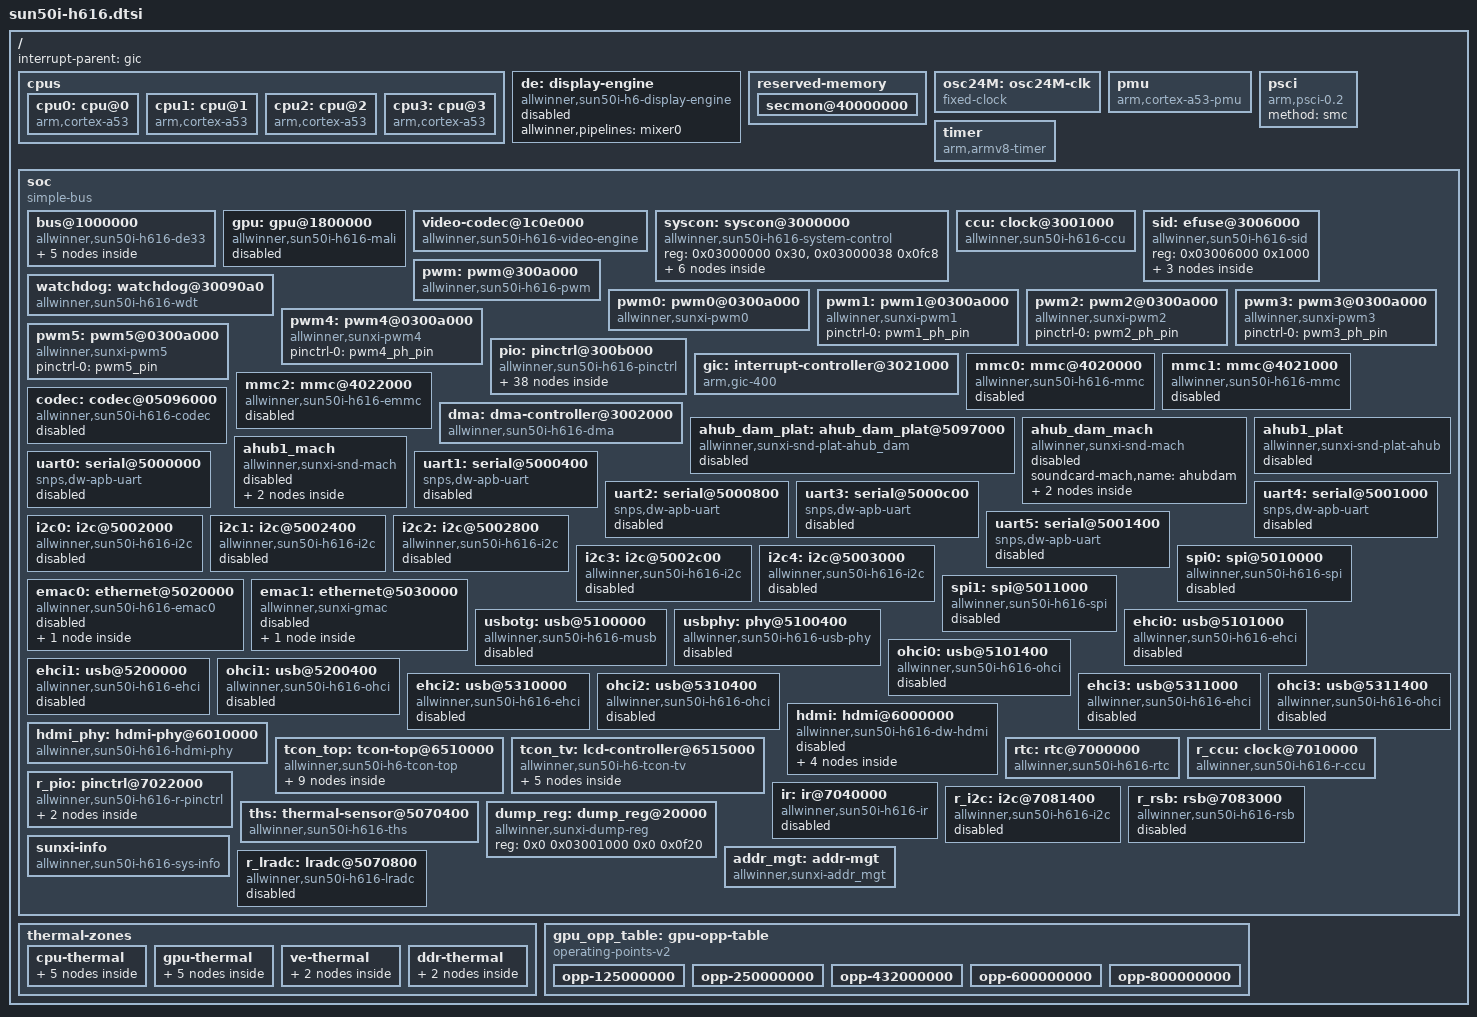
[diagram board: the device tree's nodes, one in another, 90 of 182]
// SPDX-License-Identifier: (GPL-2.0+ OR MIT)
// Copyright (C) 2020 Arm Ltd.
// based on the H6 dtsi, which is:
//   Copyright (C) 2017 Icenowy Zheng <icenowy@aosc.io>

#include <dt-bindings/interrupt-controller/arm-gic.h>
#include <dt-bindings/clock/sun50i-h616-ccu.h>
#include <dt-bindings/clock/sun50i-h6-r-ccu.h>
#include <dt-bindings/clock/sun6i-rtc.h>
#include <dt-bindings/clock/sun8i-de2.h>
#include <dt-bindings/clock/sun8i-tcon-top.h>
#include <dt-bindings/reset/sun50i-h616-ccu.h>
#include <dt-bindings/reset/sun50i-h6-r-ccu.h>
#include <dt-bindings/reset/sun8i-de2.h>
#include <dt-bindings/thermal/thermal.h>

/ {
	interrupt-parent = <&gic>;
	#address-cells = <2>;
	#size-cells = <2>;

	cpus {
		#address-cells = <1>;
		#size-cells = <0>;

		cpu0: cpu@0 {
			compatible = "arm,cortex-a53";
			device_type = "cpu";
			reg = <0>;
			enable-method = "psci";
			clocks = <&ccu CLK_CPUX>;
			clock-latency-ns = <244144>; /* 8 32k periods */
			#cooling-cells = <2>;
			operating-points-v2 = <&cpu_opp_table>;
		};

		cpu1: cpu@1 {
			compatible = "arm,cortex-a53";
			device_type = "cpu";
			reg = <1>;
			enable-method = "psci";
			clocks = <&ccu CLK_CPUX>;
			clock-latency-ns = <244144>; /* 8 32k periods */
			#cooling-cells = <2>;
			operating-points-v2 = <&cpu_opp_table>;
		};

		cpu2: cpu@2 {
			compatible = "arm,cortex-a53";
			device_type = "cpu";
			reg = <2>;
			enable-method = "psci";
			clocks = <&ccu CLK_CPUX>;
			clock-latency-ns = <244144>; /* 8 32k periods */
			#cooling-cells = <2>;
			operating-points-v2 = <&cpu_opp_table>;
		};

		cpu3: cpu@3 {
			compatible = "arm,cortex-a53";
			device_type = "cpu";
			reg = <3>;
			enable-method = "psci";
			clocks = <&ccu CLK_CPUX>;
			clock-latency-ns = <244144>; /* 8 32k periods */
			#cooling-cells = <2>;
			operating-points-v2 = <&cpu_opp_table>;
		};
	};

	de: display-engine {
		compatible = "allwinner,sun50i-h6-display-engine";
		allwinner,pipelines = <&mixer0>;
		status = "disabled";
	};

	reserved-memory {
		#address-cells = <2>;
		#size-cells = <2>;
		ranges;

		/*
		 * 512 KiB reserved for Trusted Firmware-A (BL31).
		 * This is added by BL31 itself, but some bootloaders fail
		 * to propagate this into the DTB handed to kernels.
		 */
		secmon@40000000 {
			reg = <0x0 0x40000000 0x0 0x80000>;
			no-map;
		};
	};

	osc24M: osc24M-clk {
		#clock-cells = <0>;
		compatible = "fixed-clock";
		clock-frequency = <24000000>;
		clock-output-names = "osc24M";
	};

	pmu {
		compatible = "arm,cortex-a53-pmu";
		interrupts = <GIC_SPI 140 IRQ_TYPE_LEVEL_HIGH>,
			     <GIC_SPI 141 IRQ_TYPE_LEVEL_HIGH>,
			     <GIC_SPI 142 IRQ_TYPE_LEVEL_HIGH>,
			     <GIC_SPI 143 IRQ_TYPE_LEVEL_HIGH>;
		interrupt-affinity = <&cpu0>, <&cpu1>, <&cpu2>, <&cpu3>;
	};

	psci {
		compatible = "arm,psci-0.2";
		method = "smc";
	};

	timer {
		compatible = "arm,armv8-timer";
		arm,no-tick-in-suspend;
		interrupts = <GIC_PPI 13
			(GIC_CPU_MASK_SIMPLE(4) | IRQ_TYPE_LEVEL_HIGH)>,
			     <GIC_PPI 14
			(GIC_CPU_MASK_SIMPLE(4) | IRQ_TYPE_LEVEL_HIGH)>,
			     <GIC_PPI 11
			(GIC_CPU_MASK_SIMPLE(4) | IRQ_TYPE_LEVEL_HIGH)>,
			     <GIC_PPI 10
			(GIC_CPU_MASK_SIMPLE(4) | IRQ_TYPE_LEVEL_HIGH)>;
	};

	soc {
		compatible = "simple-bus";
		#address-cells = <1>;
		#size-cells = <1>;
		ranges = <0x0 0x0 0x0 0x40000000>;

		bus@1000000 {
			compatible = "allwinner,sun50i-h616-de33",
				     "allwinner,sun50i-a64-de2";
			reg = <0x1000000 0x400000>;
			allwinner,sram = <&de3_sram 1>;
			#address-cells = <1>;
			#size-cells = <1>;
			ranges = <0 0x1000000 0x400000>;

			display_clocks: clock@8000 {
				compatible = "allwinner,sun50i-h616-de33-clk";
				reg = <0x8000 0x100>;
				clocks = <&ccu CLK_DE>, <&ccu CLK_BUS_DE>;
				clock-names = "mod", "bus";
				resets = <&ccu RST_BUS_DE>;
				#clock-cells = <1>;
				#reset-cells = <1>;
			};

			mixer0: mixer@100000 {
				compatible = "allwinner,sun50i-h616-de33-mixer-0";
				reg = <0x100000 0x100000>,
				      <0x8100 0x40>,
				      <0x280000 0x20000>;
				clocks = <&display_clocks CLK_BUS_MIXER0>,
					 <&display_clocks CLK_MIXER0>;
				clock-names = "bus", "mod";
				resets = <&display_clocks RST_MIXER0>;

				ports {
					#address-cells = <1>;
					#size-cells = <0>;

					mixer0_out: port@1 {
						reg = <1>;

						mixer0_out_tcon_top_mixer0: endpoint {
							remote-endpoint = <&tcon_top_mixer0_in_mixer0>;
						};
					};
				};
			};
		};

		gpu: gpu@1800000 {
			compatible = "allwinner,sun50i-h616-mali",
			             "arm,mali-bifrost";
			reg = <0x1800000 0x40000>;
			interrupts = <GIC_SPI 95 IRQ_TYPE_LEVEL_HIGH>,
			             <GIC_SPI 96 IRQ_TYPE_LEVEL_HIGH>,
			             <GIC_SPI 97 IRQ_TYPE_LEVEL_HIGH>;
			interrupt-names = "job", "mmu", "gpu";
			clocks = <&ccu CLK_GPU0>, <&ccu CLK_BUS_GPU>;
			clock-names = "core", "bus";
			resets = <&ccu RST_BUS_GPU>;
			//operating-points-v2 = <&gpu_opp_table>;
			//#cooling-cells = <2>;
			status = "disabled";
		};

		video-codec@1c0e000 {
			compatible = "allwinner,sun50i-h616-video-engine";
			reg = <0x01c0e000 0x2000>;
			clocks = <&ccu CLK_BUS_VE>, <&ccu CLK_VE>,
				 <&ccu CLK_MBUS_VE>;
			clock-names = "ahb", "mod", "ram";
			resets = <&ccu RST_BUS_VE>;
			interrupts = <GIC_SPI 93 IRQ_TYPE_LEVEL_HIGH>;
			allwinner,sram = <&ve_sram 1>;
		};

		syscon: syscon@3000000 {
			compatible = "allwinner,sun50i-h616-system-control";
			reg = <0x03000000 0x30>,<0x03000038 0x0fc8>;
			#address-cells = <1>;
			#size-cells = <1>;
			ranges;

			sram_a2: sram@100000 {
				compatible = "mmio-sram";
				reg = <0x00100000 0x18000>;
				#address-cells = <1>;
				#size-cells = <1>;
				ranges = <0 0x00100000 0x18000>;

				scpi_sram: scpi-sram@17c00 {
					compatible = "arm,scp-shmem";
					reg = <0x17c00 0x200>;
				};
			};

			sram_c: sram@28000 {
				compatible = "mmio-sram";
				reg = <0x00028000 0x30000>;
				#address-cells = <1>;
				#size-cells = <1>;
				ranges = <0 0x00028000 0x30000>;

				de3_sram: sram-section@0 {
					compatible = "allwinner,sun50i-h616-sram-c",
						     "allwinner,sun50i-a64-sram-c";
					reg = <0x0000 0x1e000>;
				};
			};

			sram_c1: sram@1a00000 {
				compatible = "mmio-sram";
				reg = <0x01a00000 0x200000>;
				#address-cells = <1>;
				#size-cells = <1>;
				ranges = <0 0x01a00000 0x200000>;

				ve_sram: sram-section@0 {
					compatible = "allwinner,sun50i-h616-sram-c1";
					reg = <0x000000 0x200000>;
				};
			};
		};

		ccu: clock@3001000 {
			compatible = "allwinner,sun50i-h616-ccu";
			reg = <0x03001000 0x1000>;
			clocks = <&osc24M>, <&rtc CLK_OSC32K>, <&rtc CLK_IOSC>;
			clock-names = "hosc", "losc", "iosc";
			#clock-cells = <1>;
			#reset-cells = <1>;
		};

		sid: efuse@3006000 {
			compatible = "allwinner,sun50i-h616-sid";
			reg = <0x03006000 0x1000>;
			#address-cells = <1>;
			#size-cells = <1>;

			cpu_speed_grade: cpu-speed-grade@00 {
				reg = <0x00 0x02>;
			};

			ths_calibration: thermal-sensor-calibration@14 {
				reg = <0x14 0x8>;
			};

			ephy_calibration: ephy-calibration@2c {
				reg = <0x2c 0x2>;
			};
		};

		watchdog: watchdog@30090a0 {
			compatible = "allwinner,sun50i-h616-wdt",
				     "allwinner,sun6i-a31-wdt";
			reg = <0x030090a0 0x20>;
			interrupts = <GIC_SPI 50 IRQ_TYPE_LEVEL_HIGH>;
			clocks = <&osc24M>;
			status = "okay";
		};

		pwm: pwm@300a000 {
			compatible = "allwinner,sun50i-h616-pwm";
			reg = <0x0300a000 0x400>;
			clocks = <&osc24M>, <&ccu CLK_BUS_PWM>;
			clock-names = "mod", "bus";
			resets = <&ccu RST_BUS_PWM>;
			pwm-number = <6>;
			pwm-base = <0x0>;
			sunxi-pwms = <&pwm0>, <&pwm1>, <&pwm2>, <&pwm3>, <&pwm4>, <&pwm5>;
			#pwm-cells = <3>;
			status = "okay";
		};

		pwm0: pwm0@0300a000 {
			compatible = "allwinner,sunxi-pwm0";
		};

		pwm1: pwm1@0300a000 {
			compatible = "allwinner,sunxi-pwm1";
			pinctrl-names = "default";
			pinctrl-0 = <&pwm1_ph_pin>;
		};

		pwm2: pwm2@0300a000 {
			compatible = "allwinner,sunxi-pwm2";
			pinctrl-names = "default";
			pinctrl-0 = <&pwm2_ph_pin>;
		};

		pwm3: pwm3@0300a000 {
			compatible = "allwinner,sunxi-pwm3";
			pinctrl-names = "default";
			pinctrl-0 = <&pwm3_ph_pin>;
		};

		pwm4: pwm4@0300a000 {
			compatible = "allwinner,sunxi-pwm4";
			pinctrl-names = "default";
			pinctrl-0 = <&pwm4_ph_pin>;
		};

		pwm5: pwm5@0300a000 {
			compatible = "allwinner,sunxi-pwm5";
			pinctrl-names = "default";
			pinctrl-0 = <&pwm5_pin>;
		};

		pio: pinctrl@300b000 {
			compatible = "allwinner,sun50i-h616-pinctrl";
			reg = <0x0300b000 0x400>;
			interrupts = <GIC_SPI 51 IRQ_TYPE_LEVEL_HIGH>,
				     <GIC_SPI 52 IRQ_TYPE_LEVEL_HIGH>,
				     <GIC_SPI 53 IRQ_TYPE_LEVEL_HIGH>,
				     <GIC_SPI 43 IRQ_TYPE_LEVEL_HIGH>,
				     <GIC_SPI 54 IRQ_TYPE_LEVEL_HIGH>,
				     <GIC_SPI 55 IRQ_TYPE_LEVEL_HIGH>,
				     <GIC_SPI 56 IRQ_TYPE_LEVEL_HIGH>,
				     <GIC_SPI 57 IRQ_TYPE_LEVEL_HIGH>;
			clocks = <&ccu CLK_APB1>, <&osc24M>, <&rtc CLK_OSC32K>;
			clock-names = "apb", "hosc", "losc";
			gpio-controller;
			#gpio-cells = <3>;
			interrupt-controller;
			#interrupt-cells = <3>;

			ext_rgmii_pins: rgmii-pins {
				pins = "PI0", "PI1", "PI2", "PI3", "PI4",
				       "PI5", "PI7", "PI8", "PI9", "PI10",
				       "PI11", "PI12", "PI13", "PI14", "PI15",
				       "PI16";
				function = "emac0";
				drive-strength = <40>;
			};

			/omit-if-no-ref/
			i2c0_pi_pins: i2c0-pi-pins {
				pins = "PI5", "PI6";
				function = "i2c0";
			};

			/omit-if-no-ref/
			i2c1_ph_pins: i2c1-ph-pins {
				pins = "PH0", "PH1";
				function = "i2c1";
			};

			/omit-if-no-ref/
			i2c1_pi_pins: i2c1-pi-pins {
				pins = "PI7", "PI8";
				function = "i2c1";
			};

			/omit-if-no-ref/
			i2c2_ph_pins: i2c2-ph-pins {
				pins = "PH2", "PH3";
				function = "i2c2";
			};

			/omit-if-no-ref/
			i2c2_pi_pins: i2c2-pi-pins {
				pins = "PI9", "PI10";
				function = "i2c2";
			};

			/omit-if-no-ref/
			i2c3_ph_pins: i2c3-ph-pins {
				pins = "PH4", "PH5";
				function = "i2c3";
			};

			i2c3_pa_pins: i2c3-pa-pins {
				pins = "PA10", "PA11";
				function = "i2c3";
				bias-pull-up;
			};

			/omit-if-no-ref/
			i2c4_ph_pins: i2c4-ph-pins {
				pins = "PH6", "PH7";
				function = "i2c4";
			};

			/omit-if-no-ref/
			i2s3_pins: i2s3-pins {
				pins = "PH5", "PH6", "PH7", "PH8", "PH9";
				function = "i2s3";
			};

			ir_rx_pin: ir-rx-pin {
				pins = "PH10";
				function = "ir_rx";
			};

			/omit-if-no-ref/
			pwm1_ph_pin: pwm1-ph-pin {
				pins = "PH3";
				function = "pwm1";
			};

			/omit-if-no-ref/
			pwm2_ph_pin: pwm2-ph-pin {
				pins = "PH2";
				function = "pwm2";
			};

			/omit-if-no-ref/
			pwm3_ph_pin: pwm3-ph-pin {
				pins = "PH0";
				function = "pwm3";
			};

			/omit-if-no-ref/
			pwm4_ph_pin: pwm4-ph-pin {
				pins = "PH1";
				function = "pwm4";
			};

			/omit-if-no-ref/
			pwm5_pin: pwm5-pin {
				pins = "PA12";
				function = "pwm5";
			};

			/omit-if-no-ref/
			pwm1_pi_pin: pwm1-pi-pin {
				pins = "PI11";
				function = "pwm1";
			};

			/omit-if-no-ref/
			pwm2_pi_pin: pwm2-pi-pin {
				pins = "PI12";
				function = "pwm2";
			};

			/omit-if-no-ref/
			pwm3_pi_pin: pwm3-pi-pin {
				pins = "PI13";
				function = "pwm3";
			};

			/omit-if-no-ref/
			pwm4_pi_pin: pwm4-pi-pin {
				pins = "PI14";
				function = "pwm4";
			};

			mmc0_pins: mmc0-pins {
				pins = "PF0", "PF1", "PF2", "PF3",
				       "PF4", "PF5";
				function = "mmc0";
				drive-strength = <30>;
				bias-pull-up;
			};

			/omit-if-no-ref/
			mmc1_pins: mmc1-pins {
				pins = "PG0", "PG1", "PG2", "PG3",
				       "PG4", "PG5";
				function = "mmc1";
				drive-strength = <30>;
				bias-pull-up;
			};

			mmc2_pins: mmc2-pins {
				pins = "PC0", "PC1", "PC5", "PC6",
				       "PC8", "PC9", "PC10", "PC11",
				       "PC13", "PC14", "PC15", "PC16";
				function = "mmc2";
				drive-strength = <30>;
				bias-pull-up;
			};

			rmii_pins: rmii-pins {
				pins = "PA0", "PA1", "PA2", "PA3", "PA4",
				       "PA5", "PA6", "PA7", "PA8", "PA9";
				function = "emac1";
				drive-strength = <40>;
			};

			/omit-if-no-ref/
			spi0_pins: spi0-pins {
				pins = "PC0", "PC2", "PC4";
				function = "spi0";
			};

			/omit-if-no-ref/
			spi0_cs0_pin: spi0-cs0-pin {
				pins = "PC3";
				function = "spi0";
			};

			/omit-if-no-ref/
			spi1_pins: spi1-pins {
				pins = "PH6", "PH7", "PH8";
				function = "spi1";
			};

			/omit-if-no-ref/
			spi1_cs0_pin: spi1-cs0-pin {
				pins = "PH5";
				function = "spi1";
			};

			/omit-if-no-ref/
			spi1_cs1_pin: spi1-cs1-pin {
				pins = "PH9";
				function = "spi1";
			};

			uart0_ph_pins: uart0-ph-pins {
				pins = "PH0", "PH1";
				function = "uart0";
			};

			/omit-if-no-ref/
			uart1_ph_pins: uart1-ph-pins {
				pins = "PG6", "PG7";
				function = "uart1";
			};

			/omit-if-no-ref/
			uart1_ph_rts_cts_pins: uart1-ph-rts-cts-pins {
				pins = "PG8", "PG9";
				function = "uart1";
			};

			/omit-if-no-ref/
			uart2_ph_pins: uart2-ph-pins {
				pins = "PH5", "PH6";
				function = "uart2";
			};

			/omit-if-no-ref/
			uart2_ph_rts_cts_pins: uart2-ph-rts-cts-pins {
				pins = "PH7", "PH8";
				function = "uart2";
			};

			/omit-if-no-ref/
			uart2_pi_pins: uart2-pi-pins {
				pins = "PI5", "PI6";
				function = "uart2";
			};

			/omit-if-no-ref/
			uart3_pi_pins: uart3-pi-pins {
				pins = "PI9", "PI10";
				function = "uart3";
			};

			/omit-if-no-ref/
			uart4_pi_pins: uart4-pi-pins {
				pins = "PI13", "PI14";
				function = "uart4";
			};

			/omit-if-no-ref/
			uart5_ph_pins: uart5-ph-pins {
				pins = "PH2", "PH3";
				function = "uart5";
			};
		};

		gic: interrupt-controller@3021000 {
			compatible = "arm,gic-400";
			reg = <0x03021000 0x1000>,
			      <0x03022000 0x2000>,
			      <0x03024000 0x2000>,
			      <0x03026000 0x2000>;
			interrupts = <GIC_PPI 9 (GIC_CPU_MASK_SIMPLE(4) | IRQ_TYPE_LEVEL_HIGH)>;
			interrupt-controller;
			#interrupt-cells = <3>;
		};

		mmc0: mmc@4020000 {
			compatible = "allwinner,sun50i-h616-mmc",
				     "allwinner,sun50i-a100-mmc";
			reg = <0x04020000 0x1000>;
			clocks = <&ccu CLK_BUS_MMC0>, <&ccu CLK_MMC0>;
			clock-names = "ahb", "mmc";
			resets = <&ccu RST_BUS_MMC0>;
			reset-names = "ahb";
			interrupts = <GIC_SPI 35 IRQ_TYPE_LEVEL_HIGH>;
			pinctrl-names = "default";
			pinctrl-0 = <&mmc0_pins>;
			status = "disabled";
			max-frequency = <150000000>;
			cap-sd-highspeed;
			cap-mmc-highspeed;
			mmc-ddr-3_3v;
			cap-sdio-irq;
			#address-cells = <1>;
			#size-cells = <0>;
		};

		mmc1: mmc@4021000 {
			compatible = "allwinner,sun50i-h616-mmc",
				     "allwinner,sun50i-a100-mmc";
			reg = <0x04021000 0x1000>;
			clocks = <&ccu CLK_BUS_MMC1>, <&ccu CLK_MMC1>;
			clock-names = "ahb", "mmc";
			resets = <&ccu RST_BUS_MMC1>;
			reset-names = "ahb";
			interrupts = <GIC_SPI 36 IRQ_TYPE_LEVEL_HIGH>;
			pinctrl-names = "default";
			pinctrl-0 = <&mmc1_pins>;
			status = "disabled";
			max-frequency = <150000000>;
			cap-sd-highspeed;
			cap-mmc-highspeed;
			mmc-ddr-3_3v;
			cap-sdio-irq;
			#address-cells = <1>;
			#size-cells = <0>;
		};

		mmc2: mmc@4022000 {
			compatible = "allwinner,sun50i-h616-emmc",
				     "allwinner,sun50i-a100-emmc";
			reg = <0x04022000 0x1000>;
			clocks = <&ccu CLK_BUS_MMC2>, <&ccu CLK_MMC2>;
			clock-names = "ahb", "mmc";
			resets = <&ccu RST_BUS_MMC2>;
			reset-names = "ahb";
			interrupts = <GIC_SPI 37 IRQ_TYPE_LEVEL_HIGH>;
			pinctrl-names = "default";
			pinctrl-0 = <&mmc2_pins>;
			status = "disabled";
			max-frequency = <150000000>;
			cap-sd-highspeed;
			cap-mmc-highspeed;
			mmc-ddr-3_3v;
			cap-sdio-irq;
			#address-cells = <1>;
			#size-cells = <0>;
		};

		dma: dma-controller@3002000 {
			compatible = "allwinner,sun50i-h616-dma";
			reg = <0x03002000 0x1000>;
			interrupts = <GIC_SPI 42 IRQ_TYPE_LEVEL_HIGH>;
			clocks = <&ccu CLK_BUS_DMA>, <&ccu CLK_MBUS_DMA>;
			clock-names = "bus", "mbus";
			dma-channels = <16>;
			dma-requests = <49>;
			resets = <&ccu RST_BUS_DMA>;
			#dma-cells = <1>;
		};

		codec: codec@05096000 {
			#sound-dai-cells = <0>;
			compatible = "allwinner,sun50i-h616-codec";
			reg = <0x05096000 0x31c>;
			interrupts = <GIC_SPI 58 IRQ_TYPE_LEVEL_HIGH>;
			clocks = <&ccu CLK_BUS_AUDIO_CODEC>,
				 <&ccu CLK_AUDIO_CODEC_1X>,
				 <&ccu CLK_AUDIO_CODEC_4X>;
			clock-names = "apb", "audio-codec-1x", "audio-codec-4x";
			resets = <&ccu RST_BUS_AUDIO_CODEC>;
			dmas = <&dma 6>;
			dma-names = "tx";
			status = "disabled";
		};

		ahub_dam_plat:ahub_dam_plat@5097000 {
			#sound-dai-cells = <0>;
			/* sound card without pcm for hardware mix setting */
			compatible	= "allwinner,sunxi-snd-plat-ahub_dam";
			reg		= <0x05097000 0x1000>;
			resets		= <&ccu RST_BUS_AUDIO_HUB>;
			clocks          = <&ccu CLK_AUDIO_CODEC_1X>,
			                  <&ccu CLK_AUDIO_CODEC_4X>,
			                  <&ccu CLK_AUDIO_HUB>,
			                  <&ccu CLK_BUS_AUDIO_HUB>;
			clock-names     = "clk_pll_audio",
			                  "clk_pll_audio_4x",
			                  "clk_audio_hub",
			                  "clk_bus_audio_hub";
			status		= "disabled";
		};

		ahub_dam_mach:ahub_dam_mach {
			compatible = "allwinner,sunxi-snd-mach";
			soundcard-mach,name = "ahubdam";
			status		= "disabled";
			soundcard-mach,cpu {
				sound-dai = <&ahub_dam_plat>;
			};
			soundcard-mach,codec {
			};
		};

		ahub1_plat:ahub1_plat {
			#sound-dai-cells = <0>;
			compatible	= "allwinner,sunxi-snd-plat-ahub";
			apb_num		= <1>;	/* for dma port 4 */
			dmas		= <&dma 4>, <&dma 4>;
			dma-names	= "tx", "rx";
			playback_cma	= <128>;
			capture_cma	= <128>;
			tx_fifo_size	= <128>;
			rx_fifo_size	= <128>;

			tdm_num		= <1>;
			tx_pin		= <0>;
			rx_pin		= <0>;
			status		= "disabled";
		};

		ahub1_mach:ahub1_mach {
			compatible = "allwinner,sunxi-snd-mach";
			soundcard-mach,name = "ahubhdmi";

			soundcard-mach,format		= "i2s";
			soundcard-mach,frame-master	= <&ahub1_cpu>;
			soundcard-mach,bitclock-master	= <&ahub1_cpu>;
			/* soundcard-mach,frame-inversion; */
			/* soundcard-mach,bitclock-inversion; */
			soundcard-mach,slot-num		= <2>;
			soundcard-mach,slot-width	= <32>;
			status		= "disabled";
			ahub1_cpu: soundcard-mach,cpu {
				sound-dai = <&ahub1_plat>;
				soundcard-mach,pll-fs	= <4>;
				soundcard-mach,mclk-fs	= <0>;
			};

			ahub1_codec: soundcard-mach,codec {
				sound-dai = <&hdmi>;
			};
		};

		uart0: serial@5000000 {
			compatible = "snps,dw-apb-uart";
			reg = <0x05000000 0x400>;
			interrupts = <GIC_SPI 0 IRQ_TYPE_LEVEL_HIGH>;
			reg-shift = <2>;
			reg-io-width = <4>;
			clocks = <&ccu CLK_BUS_UART0>;
			resets = <&ccu RST_BUS_UART0>;
			status = "disabled";
		};

		uart1: serial@5000400 {
			compatible = "snps,dw-apb-uart";
			reg = <0x05000400 0x400>;
			interrupts = <GIC_SPI 1 IRQ_TYPE_LEVEL_HIGH>;
			reg-shift = <2>;
			reg-io-width = <4>;
			clocks = <&ccu CLK_BUS_UART1>;
			resets = <&ccu RST_BUS_UART1>;
			status = "disabled";
		};

		uart2: serial@5000800 {
			compatible = "snps,dw-apb-uart";
			reg = <0x05000800 0x400>;
			interrupts = <GIC_SPI 2 IRQ_TYPE_LEVEL_HIGH>;
			reg-shift = <2>;
			reg-io-width = <4>;
			clocks = <&ccu CLK_BUS_UART2>;
			resets = <&ccu RST_BUS_UART2>;
			status = "disabled";
		};

		uart3: serial@5000c00 {
			compatible = "snps,dw-apb-uart";
			reg = <0x05000c00 0x400>;
			interrupts = <GIC_SPI 3 IRQ_TYPE_LEVEL_HIGH>;
			reg-shift = <2>;
			reg-io-width = <4>;
			clocks = <&ccu CLK_BUS_UART3>;
			resets = <&ccu RST_BUS_UART3>;
			status = "disabled";
		};

		uart4: serial@5001000 {
			compatible = "snps,dw-apb-uart";
			reg = <0x05001000 0x400>;
			interrupts = <GIC_SPI 4 IRQ_TYPE_LEVEL_HIGH>;
			reg-shift = <2>;
			reg-io-width = <4>;
			clocks = <&ccu CLK_BUS_UART4>;
			resets = <&ccu RST_BUS_UART4>;
			status = "disabled";
		};

		uart5: serial@5001400 {
			compatible = "snps,dw-apb-uart";
			reg = <0x05001400 0x400>;
			interrupts = <GIC_SPI 5 IRQ_TYPE_LEVEL_HIGH>;
			reg-shift = <2>;
			reg-io-width = <4>;
			clocks = <&ccu CLK_BUS_UART5>;
			resets = <&ccu RST_BUS_UART5>;
			status = "disabled";
		};

		i2c0: i2c@5002000 {
			compatible = "allwinner,sun50i-h616-i2c",
				     "allwinner,sun8i-v536-i2c",
				     "allwinner,sun6i-a31-i2c";
			reg = <0x05002000 0x400>;
			interrupts = <GIC_SPI 6 IRQ_TYPE_LEVEL_HIGH>;
			clocks = <&ccu CLK_BUS_I2C0>;
			resets = <&ccu RST_BUS_I2C0>;
			pinctrl-names = "default";
			pinctrl-0 = <&i2c0_pi_pins>;
			status = "disabled";
			#address-cells = <1>;
			#size-cells = <0>;
		};

		i2c1: i2c@5002400 {
			compatible = "allwinner,sun50i-h616-i2c",
				     "allwinner,sun8i-v536-i2c",
				     "allwinner,sun6i-a31-i2c";
			reg = <0x05002400 0x400>;
			interrupts = <GIC_SPI 7 IRQ_TYPE_LEVEL_HIGH>;
			clocks = <&ccu CLK_BUS_I2C1>;
			resets = <&ccu RST_BUS_I2C1>;
			pinctrl-names = "default";
			pinctrl-0 = <&i2c1_ph_pins>;
			status = "disabled";
			#address-cells = <1>;
			#size-cells = <0>;
		};

		i2c2: i2c@5002800 {
			compatible = "allwinner,sun50i-h616-i2c",
				     "allwinner,sun8i-v536-i2c",
				     "allwinner,sun6i-a31-i2c";
			reg = <0x05002800 0x400>;
			interrupts = <GIC_SPI 8 IRQ_TYPE_LEVEL_HIGH>;
			clocks = <&ccu CLK_BUS_I2C2>;
			resets = <&ccu RST_BUS_I2C2>;
			pinctrl-names = "default";
			pinctrl-0 = <&i2c2_ph_pins>;
			status = "disabled";
			#address-cells = <1>;
			#size-cells = <0>;
		};

		i2c3: i2c@5002c00 {
			compatible = "allwinner,sun50i-h616-i2c",
				     "allwinner,sun8i-v536-i2c",
				     "allwinner,sun6i-a31-i2c";
			reg = <0x05002c00 0x400>;
			interrupts = <GIC_SPI 9 IRQ_TYPE_LEVEL_HIGH>;
			clocks = <&ccu CLK_BUS_I2C3>;
			resets = <&ccu RST_BUS_I2C3>;
			pinctrl-names = "default";
			pinctrl-0 = <&i2c3_ph_pins>;
			status = "disabled";
			#address-cells = <1>;
			#size-cells = <0>;
		};

		i2c4: i2c@5003000 {
			compatible = "allwinner,sun50i-h616-i2c",
				     "allwinner,sun8i-v536-i2c",
				     "allwinner,sun6i-a31-i2c";
			reg = <0x05003000 0x400>;
			interrupts = <GIC_SPI 10 IRQ_TYPE_LEVEL_HIGH>;
			clocks = <&ccu CLK_BUS_I2C4>;
			resets = <&ccu RST_BUS_I2C4>;
			pinctrl-names = "default";
			pinctrl-0 = <&i2c4_ph_pins>;
			status = "disabled";
			#address-cells = <1>;
			#size-cells = <0>;
		};

		spi0: spi@5010000 {
			compatible = "allwinner,sun50i-h616-spi",
				     "allwinner,sun8i-h3-spi";
			reg = <0x05010000 0x1000>;
			interrupts = <GIC_SPI 12 IRQ_TYPE_LEVEL_HIGH>;
			clocks = <&ccu CLK_BUS_SPI0>, <&ccu CLK_SPI0>;
			clock-names = "ahb", "mod";
			resets = <&ccu RST_BUS_SPI0>;
			pinctrl-names = "default";
			pinctrl-0 = <&spi0_pins>;
			dmas = <&dma 22>, <&dma 22>;
			dma-names = "rx", "tx";
			status = "disabled";
			#address-cells = <1>;
			#size-cells = <0>;
		};

		spi1: spi@5011000 {
			compatible = "allwinner,sun50i-h616-spi",
				     "allwinner,sun8i-h3-spi";
			reg = <0x05011000 0x1000>;
			interrupts = <GIC_SPI 13 IRQ_TYPE_LEVEL_HIGH>;
			clocks = <&ccu CLK_BUS_SPI1>, <&ccu CLK_SPI1>;
			clock-names = "ahb", "mod";
			resets = <&ccu RST_BUS_SPI1>;
			pinctrl-names = "default";
			pinctrl-0 = <&spi1_pins>, <&spi1_cs1_pin>;
			dmas = <&dma 23>, <&dma 23>;
			dma-names = "rx", "tx";
			status = "disabled";
			#address-cells = <1>;
			#size-cells = <0>;
		};

		emac0: ethernet@5020000 {
			compatible = "allwinner,sun50i-h616-emac0",
				     "allwinner,sun50i-a64-emac";
			reg = <0x05020000 0x10000>;
			interrupts = <GIC_SPI 14 IRQ_TYPE_LEVEL_HIGH>;
			interrupt-names = "macirq";
			clocks = <&ccu CLK_BUS_EMAC0>;
			clock-names = "stmmaceth";
			resets = <&ccu RST_BUS_EMAC0>;
			reset-names = "stmmaceth";
			syscon = <&syscon>;
			status = "disabled";

			mdio0: mdio {
				compatible = "snps,dwmac-mdio";
				#address-cells = <1>;
				#size-cells = <0>;
			};
		};

		emac1: ethernet@5030000 {
			compatible = "allwinner,sunxi-gmac";
			reg = <0x05030000 0x10000>,
			      <0x03000034 0x4>;
			reg-names = "gmac1_reg","ephy_reg";
			interrupts = <GIC_SPI 15 IRQ_TYPE_LEVEL_HIGH>;
			interrupt-names = "gmacirq";
			resets = <&ccu RST_BUS_EMAC1>;
			reset-names = "stmmaceth";
			clocks = <&ccu CLK_BUS_EMAC1>,<&ccu CLK_EMAC_25M>;
			clock-names = "bus-emac1","emac-25m";
			pinctrl-0 = <&rmii_pins>;
			pinctrl-names = "default";
			phy-mode = "rmii";
			tx-delay = <7>;
			rx-delay = <31>;
			phy-rst;
			gmac-power0;
			gmac-power1;
			gmac-power2;
			status = "disabled";

			mdio1: mdio {
				compatible = "ethernet-phy-ieee802.3-c22";
				#address-cells = <1>;
				#size-cells = <0>;
			};
		};

		usbotg: usb@5100000 {
			compatible = "allwinner,sun50i-h616-musb",
				     "allwinner,sun8i-h3-musb";
			reg = <0x05100000 0x0400>;
			clocks = <&ccu CLK_BUS_OTG>;
			resets = <&ccu RST_BUS_OTG>;
			interrupts = <GIC_SPI 25 IRQ_TYPE_LEVEL_HIGH>;
			interrupt-names = "mc";
			phys = <&usbphy 0>;
			phy-names = "usb";
			extcon = <&usbphy 0>;
			status = "disabled";
		};

		usbphy: phy@5100400 {
			compatible = "allwinner,sun50i-h616-usb-phy";
			reg = <0x05100400 0x24>,
			      <0x05101800 0x14>,
			      <0x05200800 0x14>,
			      <0x05310800 0x14>,
			      <0x05311800 0x14>;
			reg-names = "phy_ctrl",
				    "pmu0",
				    "pmu1",
				    "pmu2",
				    "pmu3";
			clocks = <&ccu CLK_USB_PHY0>,
				 <&ccu CLK_USB_PHY1>,
				 <&ccu CLK_USB_PHY2>,
				 <&ccu CLK_USB_PHY3>,
				 <&ccu CLK_BUS_EHCI2>;
			clock-names = "usb0_phy",
				      "usb1_phy",
				      "usb2_phy",
				      "usb3_phy",
				      "pmu2_clk";
			resets = <&ccu RST_USB_PHY0>,
				 <&ccu RST_USB_PHY1>,
				 <&ccu RST_USB_PHY2>,
				 <&ccu RST_USB_PHY3>;
			reset-names = "usb0_reset",
				      "usb1_reset",
				      "usb2_reset",
				      "usb3_reset";
			status = "disabled";
			#phy-cells = <1>;
		};

		ehci0: usb@5101000 {
			compatible = "allwinner,sun50i-h616-ehci",
				     "generic-ehci";
			reg = <0x05101000 0x100>;
			interrupts = <GIC_SPI 26 IRQ_TYPE_LEVEL_HIGH>;
			clocks = <&ccu CLK_BUS_OHCI0>,
				 <&ccu CLK_BUS_EHCI0>,
				 <&ccu CLK_USB_OHCI0>,
				 <&ccu CLK_USB_PHY2>;
			resets = <&ccu RST_BUS_OHCI0>,
				 <&ccu RST_BUS_EHCI0>,
				 <&ccu RST_USB_PHY2>;
			phys = <&usbphy 0>;
			phy-names = "usb";
			status = "disabled";
		};

		ohci0: usb@5101400 {
			compatible = "allwinner,sun50i-h616-ohci",
				     "generic-ohci";
			reg = <0x05101400 0x100>;
			interrupts = <GIC_SPI 27 IRQ_TYPE_LEVEL_HIGH>;
			clocks = <&ccu CLK_BUS_OHCI0>,
				 <&ccu CLK_USB_OHCI0>,
				 <&ccu CLK_USB_PHY2>;
			resets = <&ccu RST_BUS_OHCI0>,
				 <&ccu RST_USB_PHY2>;
			phys = <&usbphy 0>;
			phy-names = "usb";
			status = "disabled";
		};

		ehci1: usb@5200000 {
			compatible = "allwinner,sun50i-h616-ehci",
				     "generic-ehci";
			reg = <0x05200000 0x100>;
			interrupts = <GIC_SPI 28 IRQ_TYPE_LEVEL_HIGH>;
			clocks = <&ccu CLK_BUS_OHCI1>,
				 <&ccu CLK_BUS_EHCI1>,
				 <&ccu CLK_USB_OHCI1>,
				 <&ccu CLK_USB_PHY2>;
			resets = <&ccu RST_BUS_OHCI1>,
				 <&ccu RST_BUS_EHCI1>,
				 <&ccu RST_USB_PHY2>;
			phys = <&usbphy 1>;
			phy-names = "usb";
			status = "disabled";
		};

		ohci1: usb@5200400 {
			compatible = "allwinner,sun50i-h616-ohci",
				     "generic-ohci";
			reg = <0x05200400 0x100>;
			interrupts = <GIC_SPI 29 IRQ_TYPE_LEVEL_HIGH>;
			clocks = <&ccu CLK_BUS_OHCI1>,
				 <&ccu CLK_USB_OHCI1>,
				 <&ccu CLK_USB_PHY2>;
			resets = <&ccu RST_BUS_OHCI1>,
				 <&ccu RST_USB_PHY2>;
			phys = <&usbphy 1>;
			phy-names = "usb";
			status = "disabled";
		};

		ehci2: usb@5310000 {
			compatible = "allwinner,sun50i-h616-ehci",
				     "generic-ehci";
			reg = <0x05310000 0x100>;
			interrupts = <GIC_SPI 30 IRQ_TYPE_LEVEL_HIGH>;
			clocks = <&ccu CLK_BUS_OHCI2>,
				 <&ccu CLK_BUS_EHCI2>,
				 <&ccu CLK_USB_OHCI2>;
			resets = <&ccu RST_BUS_OHCI2>,
				 <&ccu RST_BUS_EHCI2>;
			phys = <&usbphy 2>;
			phy-names = "usb";
			status = "disabled";
		};

		ohci2: usb@5310400 {
			compatible = "allwinner,sun50i-h616-ohci",
				     "generic-ohci";
			reg = <0x05310400 0x100>;
			interrupts = <GIC_SPI 31 IRQ_TYPE_LEVEL_HIGH>;
			clocks = <&ccu CLK_BUS_OHCI2>,
				 <&ccu CLK_USB_OHCI2>;
			resets = <&ccu RST_BUS_OHCI2>;
			phys = <&usbphy 2>;
			phy-names = "usb";
			status = "disabled";
		};

		ehci3: usb@5311000 {
			compatible = "allwinner,sun50i-h616-ehci",
				     "generic-ehci";
			reg = <0x05311000 0x100>;
			interrupts = <GIC_SPI 32 IRQ_TYPE_LEVEL_HIGH>;
			clocks = <&ccu CLK_BUS_OHCI3>,
				 <&ccu CLK_BUS_EHCI3>,
				 <&ccu CLK_USB_OHCI3>,
				 <&ccu CLK_USB_PHY2>;
			resets = <&ccu RST_BUS_OHCI3>,
				 <&ccu RST_BUS_EHCI3>,
				 <&ccu RST_USB_PHY2>;
			phys = <&usbphy 3>;
			phy-names = "usb";
			status = "disabled";
		};

		ohci3: usb@5311400 {
			compatible = "allwinner,sun50i-h616-ohci",
				     "generic-ohci";
			reg = <0x05311400 0x100>;
			interrupts = <GIC_SPI 33 IRQ_TYPE_LEVEL_HIGH>;
			clocks = <&ccu CLK_BUS_OHCI3>,
				 <&ccu CLK_USB_OHCI3>,
				 <&ccu CLK_USB_PHY2>;
			resets = <&ccu RST_BUS_OHCI3>,
				 <&ccu RST_USB_PHY2>;
			phys = <&usbphy 3>;
			phy-names = "usb";
			status = "disabled";
		};

		hdmi: hdmi@6000000 {
			#sound-dai-cells = <0>;
			compatible = "allwinner,sun50i-h616-dw-hdmi",
				     "allwinner,sun50i-h6-dw-hdmi";
			reg = <0x06000000 0x10000>;
			reg-io-width = <1>;
			interrupts = <GIC_SPI 63 IRQ_TYPE_LEVEL_HIGH>;
			clocks = <&ccu CLK_BUS_HDMI>, <&ccu CLK_HDMI_SLOW>,
				 <&ccu CLK_HDMI>, <&ccu CLK_HDMI_CEC>,
				 <&ccu CLK_HDCP>, <&ccu CLK_BUS_HDCP>;
			clock-names = "iahb", "isfr", "tmds", "cec", "hdcp",
				      "hdcp-bus";
			resets = <&ccu RST_BUS_HDMI>, <&ccu RST_BUS_HDCP>;
			reset-names = "ctrl", "hdcp";
			phys = <&hdmi_phy>;
			phy-names = "phy";
			status = "disabled";

			ports {
				#address-cells = <1>;
				#size-cells = <0>;

				hdmi_in: port@0 {
					reg = <0>;

					hdmi_in_tcon_top: endpoint {
						remote-endpoint = <&tcon_top_hdmi_out_hdmi>;
					};
				};

				hdmi_out: port@1 {
					reg = <1>;
				};
			};
		};

		hdmi_phy: hdmi-phy@6010000 {
			compatible = "allwinner,sun50i-h616-hdmi-phy";
			reg = <0x06010000 0x10000>;
			clocks = <&ccu CLK_BUS_HDMI>, <&ccu CLK_HDMI_SLOW>;
			clock-names = "bus", "mod";
			resets = <&ccu RST_BUS_HDMI_SUB>;
			reset-names = "phy";
			#phy-cells = <0>;
		};

		tcon_top: tcon-top@6510000 {
			compatible = "allwinner,sun50i-h6-tcon-top";
			reg = <0x06510000 0x1000>;
			clocks = <&ccu CLK_BUS_TCON_TOP>,
				 <&ccu CLK_TCON_TV0>;
			clock-names = "bus",
				      "tcon-tv0";
			clock-output-names = "tcon-top-tv0";
			resets = <&ccu RST_BUS_TCON_TOP>;
			#clock-cells = <1>;

			ports {
				#address-cells = <1>;
				#size-cells = <0>;

				tcon_top_mixer0_in: port@0 {
					#address-cells = <1>;
					#size-cells = <0>;
					reg = <0>;

					tcon_top_mixer0_in_mixer0: endpoint@0 {
						reg = <0>;
						remote-endpoint = <&mixer0_out_tcon_top_mixer0>;
					};
				};

				tcon_top_mixer0_out: port@1 {
					#address-cells = <1>;
					#size-cells = <0>;
					reg = <1>;

					tcon_top_mixer0_out_tcon_tv: endpoint@2 {
						reg = <2>;
						remote-endpoint = <&tcon_tv_in_tcon_top_mixer0>;
					};
				};

				tcon_top_hdmi_in: port@4 {
					#address-cells = <1>;
					#size-cells = <0>;
					reg = <4>;

					tcon_top_hdmi_in_tcon_tv: endpoint@0 {
						reg = <0>;
						remote-endpoint = <&tcon_tv_out_tcon_top>;
					};
				};

				tcon_top_hdmi_out: port@5 {
					reg = <5>;

					tcon_top_hdmi_out_hdmi: endpoint {
						remote-endpoint = <&hdmi_in_tcon_top>;
					};
				};
			};
		};

		tcon_tv: lcd-controller@6515000 {
			compatible = "allwinner,sun50i-h6-tcon-tv",
				     "allwinner,sun8i-r40-tcon-tv";
			reg = <0x06515000 0x1000>;
			interrupts = <GIC_SPI 66 IRQ_TYPE_LEVEL_HIGH>;
			clocks = <&ccu CLK_BUS_TCON_TV0>,
				 <&tcon_top CLK_TCON_TOP_TV0>;
			clock-names = "ahb",
				      "tcon-ch1";
			resets = <&ccu RST_BUS_TCON_TV0>;
			reset-names = "lcd";

			ports {
				#address-cells = <1>;
				#size-cells = <0>;

				tcon_tv_in: port@0 {
					reg = <0>;

					tcon_tv_in_tcon_top_mixer0: endpoint {
						remote-endpoint = <&tcon_top_mixer0_out_tcon_tv>;
					};
				};

				tcon_tv_out: port@1 {
					#address-cells = <1>;
					#size-cells = <0>;
					reg = <1>;

					tcon_tv_out_tcon_top: endpoint@1 {
						reg = <1>;
						remote-endpoint = <&tcon_top_hdmi_in_tcon_tv>;
					};
				};
			};
		};

		rtc: rtc@7000000 {
			compatible = "allwinner,sun50i-h616-rtc";
			reg = <0x07000000 0x400>;
			interrupts = <GIC_SPI 104 IRQ_TYPE_LEVEL_HIGH>;
			clocks = <&r_ccu CLK_R_APB1_RTC>, <&osc24M>,
				 <&ccu CLK_PLL_SYSTEM_32K>;
			clock-names = "bus", "hosc",
				      "pll-32k";
			#clock-cells = <1>;
		};

		r_ccu: clock@7010000 {
			compatible = "allwinner,sun50i-h616-r-ccu";
			reg = <0x07010000 0x210>;
			clocks = <&osc24M>, <&rtc CLK_OSC32K>, <&rtc CLK_IOSC>,
				 <&ccu CLK_PLL_PERIPH0>;
			clock-names = "hosc", "losc", "iosc", "pll-periph";
			#clock-cells = <1>;
			#reset-cells = <1>;
		};

		r_pio: pinctrl@7022000 {
			compatible = "allwinner,sun50i-h616-r-pinctrl";
			reg = <0x07022000 0x400>;
			interrupts = <GIC_SPI 43 IRQ_TYPE_LEVEL_HIGH>;
			clocks = <&r_ccu CLK_R_APB1>, <&osc24M>,
				 <&rtc CLK_OSC32K>;
			clock-names = "apb", "hosc", "losc";
			gpio-controller;
			#gpio-cells = <3>;
			interrupt-controller;
			#interrupt-cells = <3>;

			/omit-if-no-ref/
			r_i2c_pins: r-i2c-pins {
				pins = "PL0", "PL1";
				function = "s_i2c";
			};

			r_rsb_pins: r-rsb-pins {
				pins = "PL0", "PL1";
				function = "s_rsb";
			};
		};

		ir: ir@7040000 {
			compatible = "allwinner,sun50i-h616-ir",
				     "allwinner,sun6i-a31-ir";
			reg = <0x07040000 0x400>;
			interrupts = <GIC_SPI 106 IRQ_TYPE_LEVEL_HIGH>;
			clocks = <&r_ccu CLK_R_APB1_IR>,
				 <&r_ccu CLK_IR>;
			clock-names = "apb", "ir";
			resets = <&r_ccu RST_R_APB1_IR>;
			pinctrl-names = "default";
			pinctrl-0 = <&ir_rx_pin>;
			status = "disabled";
		};

		r_i2c: i2c@7081400 {
			compatible = "allwinner,sun50i-h616-i2c",
				     "allwinner,sun8i-v536-i2c",
				     "allwinner,sun6i-a31-i2c";
			reg = <0x07081400 0x400>;
			interrupts = <GIC_SPI 105 IRQ_TYPE_LEVEL_HIGH>;
			clocks = <&r_ccu CLK_R_APB2_I2C>;
			resets = <&r_ccu RST_R_APB2_I2C>;
			status = "disabled";
			#address-cells = <1>;
			#size-cells = <0>;
		};

		r_rsb: rsb@7083000 {
			compatible = "allwinner,sun50i-h616-rsb",
				     "allwinner,sun8i-a23-rsb";
			reg = <0x07083000 0x400>;
			interrupts = <GIC_SPI 109 IRQ_TYPE_LEVEL_HIGH>;
			clocks = <&r_ccu CLK_R_APB2_RSB>;
			clock-frequency = <3000000>;
			resets = <&r_ccu RST_R_APB2_RSB>;
			pinctrl-names = "default";
			pinctrl-0 = <&r_rsb_pins>;
			status = "disabled";
			#address-cells = <1>;
			#size-cells = <0>;
		};

		ths: thermal-sensor@5070400 {
			/* The Thermal Sensor Controller(THS) embeds four thermal sensors,
			sensor0 is located in GPU
			sensor1 is located in VE
			sensor2 is located in CPU
			sensor3 is located in DDR
			*/
			compatible = "allwinner,sun50i-h616-ths";
			reg = <0x05070400 0x400>;
			interrupts = <GIC_SPI 19 IRQ_TYPE_LEVEL_HIGH>;
			clocks = <&ccu CLK_BUS_THS>;
			clock-names = "bus";
			resets = <&ccu RST_BUS_THS>;
			nvmem-cells = <&ths_calibration>;
			nvmem-cell-names = "calibration";
			#thermal-sensor-cells = <1>;
		};

		dump_reg: dump_reg@20000 {
			compatible = "allwinner,sunxi-dump-reg";
			reg = <0x0 0x03001000 0x0 0x0f20>;
			status = "okay";
		};

		sunxi-info {
			compatible = "allwinner,sun50i-h616-sys-info";
			status = "okay";
		};

		addr_mgt: addr-mgt {
			compatible = "allwinner,sunxi-addr_mgt";
			type_addr_wifi = <0x2>;
			type_addr_bt = <0x2>;
			type_addr_eth = <0x2>;
			status = "okay";
		};

		r_lradc: lradc@5070800 {
			compatible = "allwinner,sun50i-h616-lradc";
			reg = <0x05070800 0x400>;
			interrupts = <GIC_SPI 20 IRQ_TYPE_EDGE_RISING>;
			clocks = <&ccu CLK_BUS_KEYADC>;
			resets = <&ccu RST_BUS_KEYADC>;
			status = "disabled";
		};
	};

	thermal-zones {
		cpu-thermal {
			polling-delay-passive = <0>;
			polling-delay = <0>;
			thermal-sensors = <&ths 2>;

			trips {
				cpu_alert: cpu-alert {
					temperature = <85000>;
					hysteresis = <2000>;
					type = "passive";
				};

				cpu-crit {
					temperature = <100000>;
					hysteresis = <0>;
					type = "critical";
				};
			};

			cooling-maps {
				map0 {
					trip = <&cpu_alert>;
					cooling-device = <&cpu0 THERMAL_NO_LIMIT THERMAL_NO_LIMIT>,
					                 <&cpu1 THERMAL_NO_LIMIT THERMAL_NO_LIMIT>,
					                 <&cpu2 THERMAL_NO_LIMIT THERMAL_NO_LIMIT>,
					                 <&cpu3 THERMAL_NO_LIMIT THERMAL_NO_LIMIT>;
				};
			};
		};

		gpu-thermal {
			polling-delay-passive = <0>;
			polling-delay = <0>;
			thermal-sensors = <&ths 0>;

			trips {
				gpu_alert: gpu-alert {
					temperature = <85000>;
					hysteresis = <2000>;
					type = "passive";
				};

				gpu-crit {
					temperature = <100000>;
					hysteresis = <0>;
					type = "critical";
				};
			};

			cooling-maps {
				map0 {
					trip = <&gpu_alert>;
					cooling-device = <&gpu THERMAL_NO_LIMIT THERMAL_NO_LIMIT>;
				};
			};
		};

		ve-thermal {
			polling-delay-passive = <0>;
			polling-delay = <0>;
			thermal-sensors = <&ths 1>;

			trips {
				ve_alert: ve-alert {
					temperature = <85000>;
					hysteresis = <2000>;
					type = "passive";
				};
			};
		};

		ddr-thermal {
			polling-delay-passive = <0>;
			polling-delay = <0>;
			thermal-sensors = <&ths 3>;

			trips {
				ddr_alert: ddr-alert {
					temperature = <85000>;
					hysteresis = <2000>;
					type = "passive";
				};
			};
		};
	};

	gpu_opp_table: gpu-opp-table {
		compatible = "operating-points-v2";
		opp-125000000 {
			opp-hz = /bits/ 64 <125000000>;
			opp-microvolt = <810000>;
		};
		opp-250000000 {
			opp-hz = /bits/ 64 <250000000>;
			opp-microvolt = <810000>;
		};
		opp-432000000 {
			opp-hz = /bits/ 64 <432000000>;
			opp-microvolt = <810000>;
		};
		opp-600000000 {
			opp-hz = /bits/ 64 <600000000>;
			opp-microvolt = <960000>;
		};
		opp-800000000 {
			opp-hz = /bits/ 64 <800000000>;
			opp-microvolt = <1080000>;
		};
	};
};
